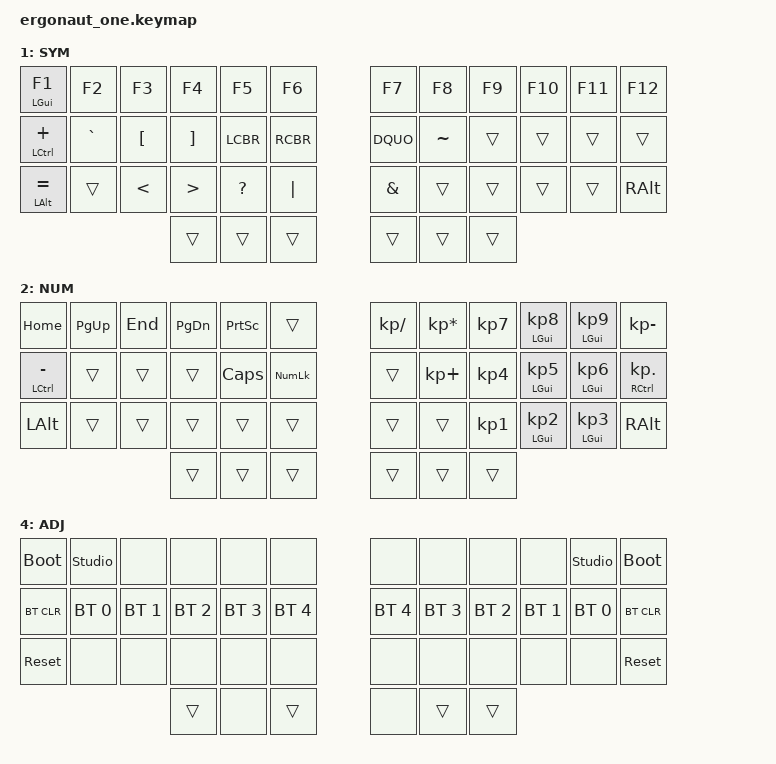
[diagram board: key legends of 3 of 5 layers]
#include <behaviors.dtsi>
#include <dt-bindings/zmk/bt.h>
#include <dt-bindings/zmk/keys.h>

#define DEF 0
#define LWR 1
#define RSE 2
#define MEDIA 5
#define ADJ 3

&lt { quick-tap-ms = <200>; };

&mt { quick-tap-ms = <200>; };

// Макрос для NULL (приоритет 1, часто в запросах 1С)
&macro_null {
    bindings = <
        &text "NULL"
        &kp SPC
    >;
};

// Макрос для <> (не равно, приоритет 1, авто-вставка пары)
&macro_not_equal {
    bindings = <
        &text "<>"
    >;
};

// Macro для Ё/Ё (hold E)
&macro_e {
    bindings = <
        &text "Ё"
    >;
};

&macro_e_upper {
    bindings = <
        &text "Ё"  // Или "Ё" uppercase, если нужно &kp LSHFT &text "Ё"
    >;
};

// Tap-dance для <>: tap <, double-tap <>, hold macro <>
&td_lt {
    tap-action = &kp LT;
    taps = <2>;
    double-tap-action = &macro_not_equal;
    hold-action = &macro_not_equal;
    hold-trigger-key-positions = <0 0 0 0>;
};

/ {
    conditional_layers {
        compatible = "zmk,conditional-layers";

        tri-layer {
            if-layers = <LWR RSE>;
            then-layer = <ADJ>;
        };
    };

    keymap {
        compatible = "zmk,keymap";

        default_layer {
            display-name = "MAIN";
            bindings = <
&mt LGUI LPAR    &kp Q  &kp W  &kp E        &kp R            &kp T        &kp Y          &kp U           &kp I        &kp O    &kp P     &kp RPAR
&mt LCTRL GRAVE  &kp A  &kp S  &kp D        &mt LSHFT E      &kp G        &kp H          &kp J           &kp K        &kp L    &kp SEMI  &mt RCTRL SQT
&mt LALT MINUS   &kp Z  &kp X  &kp C        &kp V            &kp B        &kp N          &kp M           &mt LSHFT COMMA &mt LSHFT DOT  &kp FSLH  &mt RALT BSLH
                               &mo LWR TAB  &lt ADJ SPACE  &mo RSE RET  &lt MEDIA ESC  &mt RSHFT BSPC  &mo LWR DEL
            >;
        };

        lower_layer {
            display-name = "SYM";
            bindings = <
&mt LGUI F1     &kp F2  &kp F3  &kp F4  &kp F5  &kp F6  &kp F7    &kp F8    &kp F9          &kp F10          &kp F11            &kp F12
&mt LCTRL PLUS  &kp GRAVE &kp LBKT &kp RBKT &kp LCBR &kp RCBR  &kp DQUO  &kp TILDE &trans          &trans            &trans             &trans
&mt LALT EQUAL  &trans    &kp LT   &kp GT   &kp QMARK &kp PIPE &kp AMPS  &trans    &trans          &trans            &trans             &kp RALT
                                &trans  &trans  &trans  &trans    &trans    &trans
            >;
        };

        raise_layer {
            display-name = "NUM";
            bindings = <
&kp HOME        &kp PG_UP &kp END  &kp PG_DN &kp PSCRN &trans    &kp KP_SLASH  &kp KP_MULTIPLY  &kp KP_N7  &mt LGUI KP_N8  &mt LGUI KP_N9  &kp KP_MINUS
&mt LCTRL MINUS &trans     &trans   &trans    &kp CAPS  &kp KP_NUM &trans       &kp KP_PLUS      &kp KP_N4  &mt LGUI KP_N5  &mt LGUI KP_N6  &mt RCTRL KP_DOT
&kp LALT        &trans     &trans   &trans    &trans    &trans     &trans       &trans           &kp KP_N1  &mt LGUI KP_N2  &mt LGUI KP_N3  &kp RALT
                                           &trans     &trans     &trans    &trans        &trans           &trans
            >;
        };

        media_layer {
            display-name = "MEDIA";
            bindings = <
&trans  &trans  &trans  &trans  &trans                &trans                &trans                &trans           &trans                         &trans                  &trans  &trans
&trans  &trans  &trans  &trans  &trans                &trans                &trans                &kp C_MUTE       &kp C_VOLUME_DOWN              &kp C_VOLUME_UP          &trans  &trans
&trans  &trans  &trans  &trans  &trans                &trans                &trans                &kp C_PREVIOUS   &kp C_PLAY_PAUSE                &kp C_STOP               &kp C_NEXT &kp C_REWIND
                        &trans  &trans                &trans                &trans                &trans                &trans                &kp C_FAST_FORWARD
            >;
        };

        adjust_layer {
            display-name = "ADJ";
            bindings = <
&bootloader  &studio_unlock  &none         &none         &none         &none         &none         &none         &none         &none         &studio_unlock  &bootloader
&bt BT_CLR   &bt BT_SEL 0    &bt BT_SEL 1  &bt BT_SEL 2  &bt BT_SEL 3  &bt BT_SEL 4  &bt BT_SEL 4  &bt BT_SEL 3  &bt BT_SEL 2  &bt BT_SEL 1  &bt BT_SEL 0    &bt BT_CLR
&sys_reset   &none           &none         &none         &none         &none         &none         &none         &none         &none         &none           &sys_reset
                                           &trans        &none         &trans        &none         &trans        &trans
            >;
        };
    };
};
